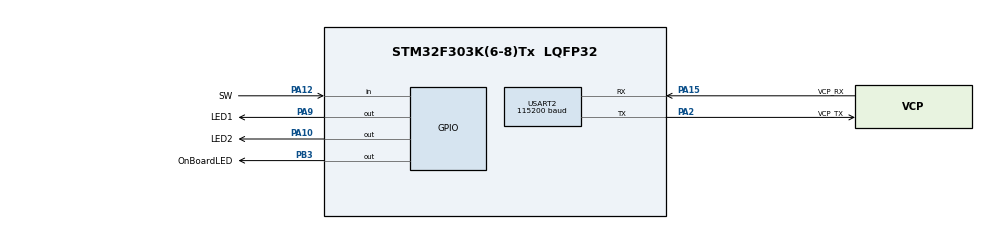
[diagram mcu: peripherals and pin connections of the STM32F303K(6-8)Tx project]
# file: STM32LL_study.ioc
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Mcu.Family=STM32F3
Mcu.Name=STM32F303K(6-8)Tx
Mcu.Package=LQFP32
NVIC.PriorityGroup=NVIC_PRIORITYGROUP_4
PA10.GPIO_Label=LED2
PA10.Signal=GPIO_Output
PA12.GPIO_Label=SW
PA12.Signal=GPIO_Input
PA13.GPIO_Label=SWDIO
PA13.Mode=Serial_Wire
PA13.Signal=SYS_JTMS-SWDIO
PA14.GPIO_Label=SWCLK
PA14.Mode=Serial_Wire
PA14.Signal=SYS_JTCK-SWCLK
PA15.GPIO_Label=VCP_RX
PA15.Mode=Asynchronous
PA15.Signal=USART2_RX
PA2.GPIO_Label=VCP_TX
PA2.Mode=Asynchronous
PA2.Signal=USART2_TX
PA9.GPIO_Label=LED1
PA9.Signal=GPIO_Output
PB3.GPIO_Label=OnBoardLED
PB3.Signal=GPIO_Output
PF0\ /\ OSC_IN.GPIO_Label=MCO
PF0\ /\ OSC_IN.Mode=HSE-External-Clock-Source
PF0\ /\ OSC_IN.Signal=RCC_OSC_IN
ProjectManager.HeapSize=0x200
ProjectManager.StackSize=0x400
ProjectManager.TargetToolchain=Makefile
RCC.AHBFreq_Value=8000000
RCC.APB1Freq_Value=8000000
RCC.APB2Freq_Value=8000000
RCC.CortexFreq_Value=8000000
RCC.HSE_VALUE=8000000
RCC.HSI_VALUE=8000000
RCC.SYSCLKFreq_VALUE=8000000
USART2.BaudRate=115200
USART2.VirtualMode-Asynchronous=VM_ASYNC
board=NUCLEO-F303K8

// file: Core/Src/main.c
/* USER CODE BEGIN Header */
/**
  ******************************************************************************
  * @file           : main.c
  * @brief          : Main program body
  ******************************************************************************
  * @attention
  *
  * <h2><center>&copy; Copyright (c) 2021 STMicroelectronics.
  * All rights reserved.</center></h2>
  *
  * This software component is licensed by ST under BSD 3-Clause license,
  * the "License"; You may not use this file except in compliance with the
  * License. You may obtain a copy of the License at:
  *                        opensource.org/licenses/BSD-3-Clause
  *
  ******************************************************************************
  */
/* USER CODE END Header */
#include "main.h"
#include "usart.h"
#include "gpio.h"

/* USER CODE BEGIN Includes */
#include <stdio.h>
#include <stdint.h>
#include "yama_gpio.h"
#include "yama_uart.h"
/* USER CODE END Includes */

void SystemClock_Config(void);

/* USER CODE BEGIN 0 */

int __io_putchar(uint8_t ch)
{
  transmitUSART2Char(&ch);
  return ch;
}

/* USER CODE END 0 */

int main(void)
{
  /* USER CODE BEGIN 1 */
  setbuf(stdout, NULL);
  /* USER CODE END 1 */

  /* MCU Configuration--------------------------------------------------------*/

  /* Reset of all peripherals, Initializes the Flash interface and the Systick. */

  LL_APB2_GRP1_EnableClock(LL_APB2_GRP1_PERIPH_SYSCFG);
  LL_APB1_GRP1_EnableClock(LL_APB1_GRP1_PERIPH_PWR);

  NVIC_SetPriorityGrouping(NVIC_PRIORITYGROUP_4);

  /* System interrupt init*/

  /* Configure the system clock */
  SystemClock_Config();

  /* Initialize all configured peripherals */
  MX_GPIO_Init();
  MX_USART2_UART_Init();

  /* Infinite loop */
  while (1)
  {

    /* USER CODE BEGIN 3 */
    writeOnBoardLED(readSW());
    printf("hello world\r\n");
  }
  /* USER CODE END 3 */
}

void SystemClock_Config(void)
{
  LL_FLASH_SetLatency(LL_FLASH_LATENCY_0);
  while(LL_FLASH_GetLatency()!= LL_FLASH_LATENCY_0)
  {
  }
  LL_RCC_HSI_Enable();

   /* Wait till HSI is ready */
  while(LL_RCC_HSI_IsReady() != 1)
  {

  }
  LL_RCC_HSI_SetCalibTrimming(16);
  LL_RCC_SetAHBPrescaler(LL_RCC_SYSCLK_DIV_1);
  LL_RCC_SetAPB1Prescaler(LL_RCC_APB1_DIV_1);
  LL_RCC_SetAPB2Prescaler(LL_RCC_APB2_DIV_1);
  LL_RCC_SetSysClkSource(LL_RCC_SYS_CLKSOURCE_HSI);

   /* Wait till System clock is ready */
  while(LL_RCC_GetSysClkSource() != LL_RCC_SYS_CLKSOURCE_STATUS_HSI)
  {

  }
  LL_Init1msTick(8000000);
  LL_SetSystemCoreClock(8000000);
}

void Error_Handler(void)
{
  __disable_irq();
  while (1)
  {
  }
}

/************************ (C) COPYRIGHT STMicroelectronics *****END OF FILE****/
